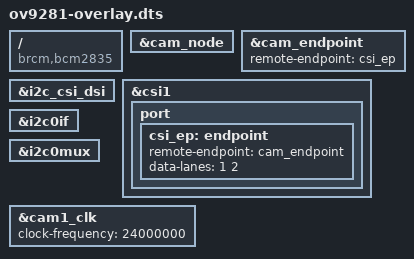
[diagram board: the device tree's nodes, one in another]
// SPDX-License-Identifier: GPL-2.0-only
// Definitions for OV9281 camera module on VC I2C bus
/dts-v1/;
/plugin/;

#include <dt-bindings/gpio/gpio.h>

/{
	compatible = "brcm,bcm2835";

	i2c_frag: fragment@0 {
		target = <&i2c_csi_dsi>;
		__overlay__ {
			#address-cells = <1>;
			#size-cells = <0>;
			status = "okay";

			#include "ov9281.dtsi"
		};
	};

	csi_frag: fragment@1 {
		target = <&csi1>;
		csi: __overlay__ {
			status = "okay";

			port {
				csi_ep: endpoint {
					remote-endpoint = <&cam_endpoint>;
					data-lanes = <1 2>;
				};
			};
		};
	};

	fragment@2 {
		target = <&i2c0if>;
		__overlay__ {
			status = "okay";
		};
	};

	fragment@3 {
		target = <&i2c0mux>;
		__overlay__ {
			status = "okay";
		};
	};

	clk_frag: fragment@4 {
		target = <&cam1_clk>;
		__overlay__ {
			status = "okay";
			clock-frequency = <24000000>;
		};
	};

	fragment@5 {
		target = <&csi1>;
		__dormant__ {
			compatible = "brcm,bcm2835-unicam-legacy";
		};
	};

	reg_frag: fragment@6 {
		target = <&cam1_reg>;
		__dormant__ {
			startup-delay-us = <20000>;
			off-on-delay-us = <30000>;
		};
	};

	__overrides__ {
		rotation = <&cam_node>,"rotation:0";
		orientation = <&cam_node>,"orientation:0";
		media-controller = <0>,"!5";
		cam0 = <&i2c_frag>, "target:0=",<&i2c_csi_dsi0>,
		       <&csi_frag>, "target:0=",<&csi0>,
		       <&clk_frag>, "target:0=",<&cam0_clk>,
		       <&cam_node>, "clocks:0=",<&cam0_clk>,
		       <&cam_node>, "avdd-supply:0=",<&cam0_reg>,
		       <&reg_frag>, "target:0=",<&cam0_reg>;
		arducam = <0>, "+6";
	};
};

&cam_node {
	status = "okay";
};

&cam_endpoint {
	remote-endpoint = <&csi_ep>;
};
